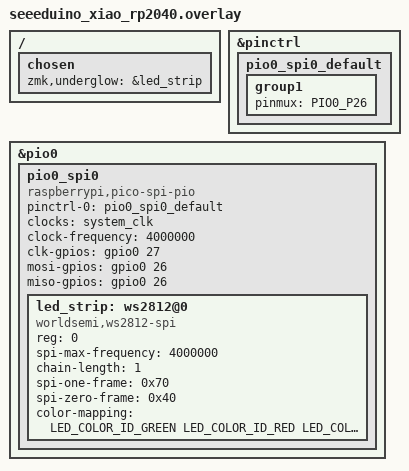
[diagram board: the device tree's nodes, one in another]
#include <dt-bindings/led/led.h>

&pinctrl {
    pio0_spi0_default: pio0_spi0_default {
        group1 {
            pinmux = <PIO0_P26>;
        };
    };
};

&pio0 {
    status = "okay";

    pio0_spi0: pio0_spi0 {
        pinctrl-0 = <&pio0_spi0_default>;
        pinctrl-names = "default";

        compatible = "raspberrypi,pico-spi-pio";
        #address-cells = <1>;
        #size-cells = <0>;
        clocks = <&system_clk>;
        clock-frequency = <4000000>;

        clk-gpios = <&gpio0 27 GPIO_ACTIVE_HIGH>;  /* D1 - dummy clock, unused but required */
        mosi-gpios = <&gpio0 26 GPIO_ACTIVE_HIGH>; /* D0 - Data In pin */
        miso-gpios = <&gpio0 26 GPIO_ACTIVE_HIGH>; /* D0 - reuse DI pin */

        led_strip: ws2812@0 {
            compatible = "worldsemi,ws2812-spi";

            reg = <0>;
            spi-max-frequency = <4000000>;

            chain-length = <1>;  /* Test with 1 LED first */
            spi-one-frame = <0x70>;
            spi-zero-frame = <0x40>;
            color-mapping = <LED_COLOR_ID_GREEN
                             LED_COLOR_ID_RED
                             LED_COLOR_ID_BLUE>;
        };
    };
};

/ {
    chosen {
        zmk,underglow = &led_strip;
    };
};
